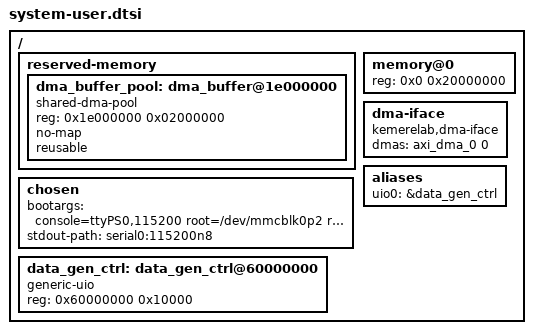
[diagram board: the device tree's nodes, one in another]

/include/ "system-conf.dtsi"
/ {
    /* Reserved memory for DMA buffers */
    reserved-memory {
        #address-cells = <1>;
        #size-cells = <1>;
        ranges;
        
        /* Large contiguous buffer for DMA operations */
        dma_buffer_pool: dma_buffer@1e000000 {
            compatible = "shared-dma-pool";
            reg = <0x1e000000 0x02000000>; /* 32MB at 480MB mark */
            no-map;
            reusable;
        };
    };
    
    chosen {
        bootargs = "console=ttyPS0,115200 root=/dev/mmcblk0p2 rw earlyprintk rootfstype=ext4 rootwait devtmpfs.mount=1 uio_pdrv_genirq.of_id=generic-uio";
        stdout-path = "serial0:115200n8";
    };
    
    memory@0 {
        device_type = "memory";
        reg = <0x0 0x20000000>; /* 512MB total memory */
    };

    /* Device that will be used to interface with axi_dma in pl.dtsi */
    dma-iface {
        compatible = "kemerelab,dma-iface";
        dmas = <&axi_dma_0 0>;         // 0 for S2MM (stream-to-memory)
        dma-names = "rx";
    };
    
    /* UIO device for user-space access */
    /* Data generator control - directly under root */
    data_gen_ctrl: data_gen_ctrl@60000000 {
        compatible = "generic-uio";
        reg = <0x60000000 0x10000>;
        status = "okay";
    };
    
    /* Aliases for easy identification */  
    aliases {
        uio0 = &data_gen_ctrl;
    };
};
